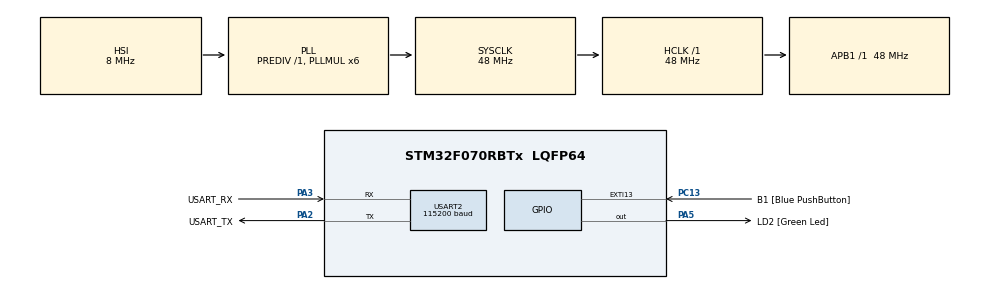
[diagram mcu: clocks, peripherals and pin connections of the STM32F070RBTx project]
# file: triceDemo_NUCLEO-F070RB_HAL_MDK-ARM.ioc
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Dma.Request0=USART2_TX
Dma.USART2_TX.0.Direction=DMA_MEMORY_TO_PERIPH
Dma.USART2_TX.0.Instance=DMA1_Channel4
Dma.USART2_TX.0.MemDataAlignment=DMA_MDATAALIGN_BYTE
Dma.USART2_TX.0.MemInc=DMA_MINC_ENABLE
Dma.USART2_TX.0.Mode=DMA_NORMAL
Dma.USART2_TX.0.PeriphDataAlignment=DMA_PDATAALIGN_BYTE
Dma.USART2_TX.0.PeriphInc=DMA_PINC_DISABLE
Dma.USART2_TX.0.Priority=DMA_PRIORITY_LOW
Mcu.Family=STM32F0
Mcu.Name=STM32F070RBTx
Mcu.Package=LQFP64
NVIC.DMA1_Channel4_5_IRQn=true\:0\:0\:false\:false\:true\:false\:true
NVIC.USART2_IRQn=true\:0\:0\:false\:false\:true\:true\:true
PA13.GPIO_Label=TMS
PA13.Mode=Serial_Wire
PA13.Signal=SYS_SWDIO
PA14.GPIO_Label=TCK
PA14.Mode=Serial_Wire
PA14.Signal=SYS_SWCLK
PA2.GPIO_Label=USART_TX
PA2.Mode=Asynchronous
PA2.Signal=USART2_TX
PA3.GPIO_Label=USART_RX
PA3.Mode=Asynchronous
PA3.Signal=USART2_RX
PA5.GPIO_Label=LD2 [Green Led]
PA5.Signal=GPIO_Output
PC13.GPIO_Label=B1 [Blue PushButton]
PC13.GPIO_ModeDefaultEXTI=GPIO_MODE_IT_FALLING
PC13.Signal=GPXTI13
PC14-OSC32_IN.GPIO_Label=RCC_OSC32_IN
PC14-OSC32_IN.Mode=LSE-External-Oscillator
PC14-OSC32_IN.Signal=RCC_OSC32_IN
PC15-OSC32_OUT.GPIO_Label=RCC_OSC32_OUT
PC15-OSC32_OUT.Mode=LSE-External-Oscillator
PC15-OSC32_OUT.Signal=RCC_OSC32_OUT
PF0-OSC_IN.GPIO_Label=RCC_OSC_IN
PF0-OSC_IN.Mode=HSE-External-Clock-Source
PF0-OSC_IN.Signal=RCC_OSC_IN
PF1-OSC_OUT.GPIO_Label=RCC_OSC_OUT
PF1-OSC_OUT.Signal=RCC_OSC_OUT
ProjectManager.HeapSize=0x200
ProjectManager.StackSize=0x400
ProjectManager.TargetToolchain=MDK-ARM V5.27
RCC.AHBFreq_Value=48000000
RCC.APB1Freq_Value=48000000
RCC.APB1TimFreq_Value=48000000
RCC.HCLKFreq_Value=48000000
RCC.PLLMUL=RCC_PLL_MUL6
RCC.SYSCLKFreq_VALUE=48000000
RCC.SYSCLKSource=RCC_SYSCLKSOURCE_PLLCLK
USART2.BaudRate=115200
USART2.VirtualMode-Asynchronous=VM_ASYNC
board=NUCLEO-F070RB

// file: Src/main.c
/* USER CODE BEGIN Header */
/**
  ******************************************************************************
  * @file           : main.c
  * @brief          : Main program body
  ******************************************************************************
  * @attention
  *
  * <h2><center>&copy; Copyright (c) 2020 STMicroelectronics.
  * All rights reserved.</center></h2>
  *
  * This software component is licensed by ST under BSD 3-Clause license,
  * the "License"; You may not use this file except in compliance with the
  * License. You may obtain a copy of the License at:
  *                        opensource.org/licenses/BSD-3-Clause
  *
  ******************************************************************************
  */
/* USER CODE END Header */

#include "main.h"

/* USER CODE BEGIN Includes */
#include "trice.h"
/* USER CODE END Includes */

UART_HandleTypeDef huart2;
DMA_HandleTypeDef hdma_usart2_tx;

void SystemClock_Config(void);
static void MX_GPIO_Init(void);
static void MX_DMA_Init(void);
static void MX_USART2_UART_Init(void);

int main(void)
{
  /* USER CODE BEGIN 1 */
#ifdef ENCRYPT
    InitXteaTable();
#endif
  /* USER CODE END 1 */

  /* MCU Configuration--------------------------------------------------------*/

  /* Reset of all peripherals, Initializes the Flash interface and the Systick. */
  HAL_Init();

  /* Configure the system clock */
  SystemClock_Config();

  /* Initialize all configured peripherals */
  MX_GPIO_Init();
  MX_DMA_Init();
  MX_USART2_UART_Init();

  /* Infinite loop */
  /* USER CODE BEGIN WHILE */
  TRICE0( Id(43213), "att:triceDemo_NUCLEO-F070RB_HAL_MDK-ARM\n" );
  while (1)
  {
      //////////////////////////////////////////////////
      // demo trices
      //
      static uint32_t ms_1 = 0;
      uint32_t ms = HAL_GetTick();
      if( ms >= ms_1 + 3000 ){ // every 3 sec
          void triceCheckSet( void );
          triceCheckSet();
          TRICE32_1( Id(29200), "time:ms = %d\n", ms );
          HAL_GPIO_TogglePin(LD2_GPIO_Port, LD2_Pin);
          ms_1 = ms;
      }
      //
      //////////////////////////////////////////////////

      //////////////////////////////////////////////////
      // needed background activity
      //
      triceServe();
      //
      //////////////////////////////////////////////////
    /* USER CODE END WHILE */

  }
}

void SystemClock_Config(void)
{
  RCC_OscInitTypeDef RCC_OscInitStruct = {0};
  RCC_ClkInitTypeDef RCC_ClkInitStruct = {0};

  /** Initializes the CPU, AHB and APB busses clocks
  */
  RCC_OscInitStruct.OscillatorType = RCC_OSCILLATORTYPE_HSI;
  RCC_OscInitStruct.HSIState = RCC_HSI_ON;
  RCC_OscInitStruct.HSICalibrationValue = RCC_HSICALIBRATION_DEFAULT;
  RCC_OscInitStruct.PLL.PLLState = RCC_PLL_ON;
  RCC_OscInitStruct.PLL.PLLSource = RCC_PLLSOURCE_HSI;
  RCC_OscInitStruct.PLL.PLLMUL = RCC_PLL_MUL6;
  RCC_OscInitStruct.PLL.PREDIV = RCC_PREDIV_DIV1;
  if (HAL_RCC_OscConfig(&RCC_OscInitStruct) != HAL_OK)
  {
    Error_Handler();
  }
  /** Initializes the CPU, AHB and APB busses clocks
  */
  RCC_ClkInitStruct.ClockType = RCC_CLOCKTYPE_HCLK|RCC_CLOCKTYPE_SYSCLK
                              |RCC_CLOCKTYPE_PCLK1;
  RCC_ClkInitStruct.SYSCLKSource = RCC_SYSCLKSOURCE_PLLCLK;
  RCC_ClkInitStruct.AHBCLKDivider = RCC_SYSCLK_DIV1;
  RCC_ClkInitStruct.APB1CLKDivider = RCC_HCLK_DIV1;

  if (HAL_RCC_ClockConfig(&RCC_ClkInitStruct, FLASH_LATENCY_1) != HAL_OK)
  {
    Error_Handler();
  }
}

static void MX_USART2_UART_Init(void)
{

  huart2.Instance = USART2;
  huart2.Init.BaudRate = 115200;
  huart2.Init.WordLength = UART_WORDLENGTH_8B;
  huart2.Init.StopBits = UART_STOPBITS_1;
  huart2.Init.Parity = UART_PARITY_NONE;
  huart2.Init.Mode = UART_MODE_TX_RX;
  huart2.Init.HwFlowCtl = UART_HWCONTROL_NONE;
  huart2.Init.OverSampling = UART_OVERSAMPLING_16;
  huart2.Init.OneBitSampling = UART_ONE_BIT_SAMPLE_DISABLE;
  huart2.AdvancedInit.AdvFeatureInit = UART_ADVFEATURE_NO_INIT;
  if (HAL_UART_Init(&huart2) != HAL_OK)
  {
    Error_Handler();
  }

}

static void MX_DMA_Init(void)
{

  /* DMA controller clock enable */
  __HAL_RCC_DMA1_CLK_ENABLE();

  /* DMA interrupt init */
  /* DMA1_Channel4_5_IRQn interrupt configuration */
  HAL_NVIC_SetPriority(DMA1_Channel4_5_IRQn, 0, 0);
  HAL_NVIC_EnableIRQ(DMA1_Channel4_5_IRQn);

}

static void MX_GPIO_Init(void)
{
  GPIO_InitTypeDef GPIO_InitStruct = {0};

  /* GPIO Ports Clock Enable */
  __HAL_RCC_GPIOC_CLK_ENABLE();
  __HAL_RCC_GPIOF_CLK_ENABLE();
  __HAL_RCC_GPIOA_CLK_ENABLE();

  /*Configure GPIO pin Output Level */
  HAL_GPIO_WritePin(LD2_GPIO_Port, LD2_Pin, GPIO_PIN_RESET);

  /*Configure GPIO pin : B1_Pin */
  GPIO_InitStruct.Pin = B1_Pin;
  GPIO_InitStruct.Mode = GPIO_MODE_IT_FALLING;
  GPIO_InitStruct.Pull = GPIO_NOPULL;
  HAL_GPIO_Init(B1_GPIO_Port, &GPIO_InitStruct);

  /*Configure GPIO pin : LD2_Pin */
  GPIO_InitStruct.Pin = LD2_Pin;
  GPIO_InitStruct.Mode = GPIO_MODE_OUTPUT_PP;
  GPIO_InitStruct.Pull = GPIO_NOPULL;
  GPIO_InitStruct.Speed = GPIO_SPEED_FREQ_LOW;
  HAL_GPIO_Init(LD2_GPIO_Port, &GPIO_InitStruct);

}

void Error_Handler(void)
{
}

/************************ (C) COPYRIGHT STMicroelectronics *****END OF FILE****/
